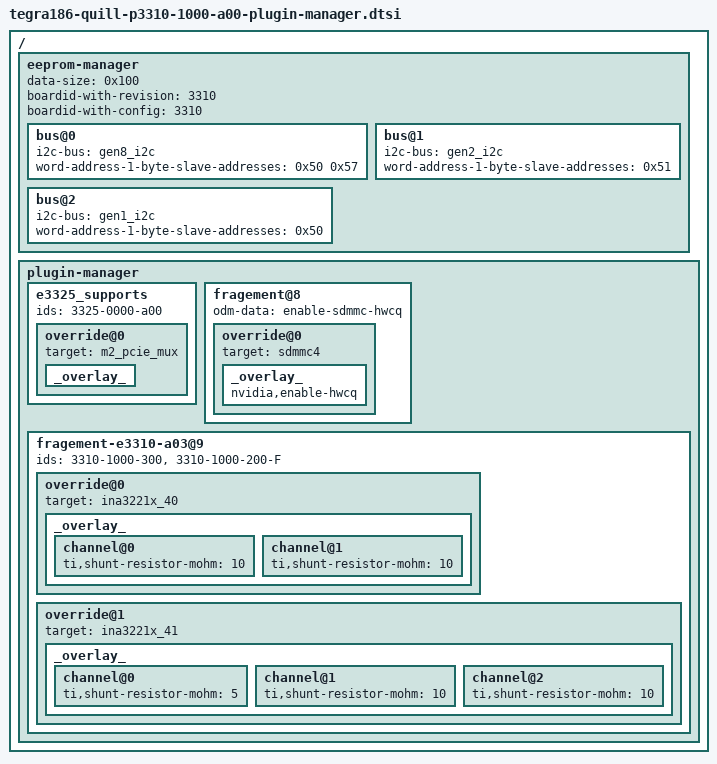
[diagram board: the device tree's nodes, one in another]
/*
 * tegra186-quill-p3310-1000-a00-plugin-manager.dtsi: P3310 plugin manager
 *
 * Copyright (c) 2015-2016, NVIDIA CORPORATION.  All rights reserved.
 *
 * This program is free software; you can redistribute it and/or modify
 * it under the terms of the GNU General Public License as published by
 * the Free Software Foundation; version 2 of the License.
 *
 * This program is distributed in the hope that it will be useful, but WITHOUT
 * ANY WARRANTY; without even the implied warranty of MERCHANTABILITY or
 * FITNESS FOR A PARTICULAR PURPOSE.  See the GNU General Public License for
 * more details.
 */

#include "tegra186-quill-odm-data-plugin-manager.dtsi"

/ {
	eeprom-manager {
		data-size = <0x100>;
		boardid-with-revision = <3310>;
		boardid-with-config = <3310>;
		bus@0 {
			i2c-bus = <&gen8_i2c>;
			word-address-1-byte-slave-addresses = <0x50 0x57>;
		};
		bus@1 {
			i2c-bus = <&gen2_i2c>;
			word-address-1-byte-slave-addresses = <0x51>;
		};
		bus@2 {
			i2c-bus = <&gen1_i2c>;
			word-address-1-byte-slave-addresses = <0x50>;
		};

	};

	plugin-manager {
		e3325_supports {
			ids = "3325-0000-a00";
			override@0 {
				target = <&m2_pcie_mux>;
				_overlay_ {
					status = "okay";
				};
			};
		};

		fragement@8 {
			odm-data = "enable-sdmmc-hwcq";
			override@0 {
				target = <&sdmmc4>;
				_overlay_ {
					nvidia,enable-hwcq;
				};
			};
		};

		fragement-e3310-a03@9 {
			ids = "3310-1000-300", "3310-1000-200-F";
			override@0 {
				target = <&ina3221x_40>;
				_overlay_ {
					channel@0 {
						ti,shunt-resistor-mohm = <10>;
					};
					channel@1 {
						ti,shunt-resistor-mohm = <10>;
					};
				};
			};

			override@1 {
				target = <&ina3221x_41>;
				_overlay_ {
					channel@0 {
						ti,shunt-resistor-mohm = <5>;
					};
					channel@1 {
						ti,shunt-resistor-mohm = <10>;
					};
					channel@2 {
						ti,shunt-resistor-mohm = <10>;
					};
				};
			};
		};
	};
};
